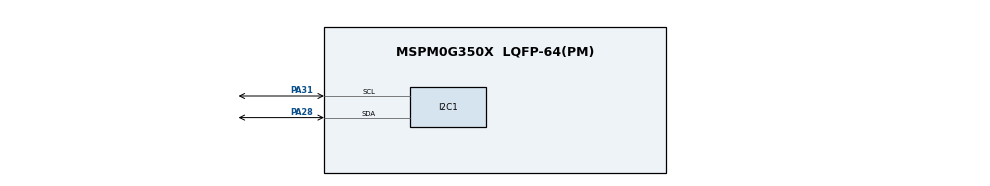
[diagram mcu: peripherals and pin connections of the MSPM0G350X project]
/**
 * @cliArgs --device "MSPM0G350X" --package "LQFP-64(PM)" --part "Default" --product "mspm0_sdk@2.01.00.03"
 * @versions {"tool":"1.20.0+3587"}
 */

/**
 * Import the modules used in this configuration.
 */
const ADC12         = scripting.addModule("/ti/driverlib/ADC12", {}, false);
const ADC121        = ADC12.addInstance();
const ADC122        = ADC12.addInstance();
const CAPTURE       = scripting.addModule("/ti/driverlib/CAPTURE", {}, false);
const CAPTURE1      = CAPTURE.addInstance();
const I2C           = scripting.addModule("/ti/driverlib/I2C", {}, false);
const I2C1          = I2C.addInstance();
const SYSCTL        = scripting.addModule("/ti/driverlib/SYSCTL");
const TIMER         = scripting.addModule("/ti/driverlib/TIMER", {}, false);
const TIMER1        = TIMER.addInstance();
const ProjectConfig = scripting.addModule("/ti/project_config/ProjectConfig");

/**
 * Write custom configuration values to the imported modules.
 */
ADC121.$name                          = "ADC12_0";
ADC121.repeatMode                     = true;
ADC121.adcMem0trig                    = "DL_ADC12_TRIGGER_MODE_TRIGGER_NEXT";
ADC121.configureDMA                   = true;
ADC121.subChanID                      = 1;
ADC121.powerDownMode                  = "DL_ADC12_POWER_DOWN_MODE_MANUAL";
ADC121.trigSrc                        = "DL_ADC12_TRIG_SRC_EVENT";
ADC121.adcMem0chansel                 = "DL_ADC12_INPUT_CHAN_2";
ADC121.sampleTime0                    = "40us";
ADC121.sampCnt                        = 1;
ADC121.enabledDMATriggers             = ["DL_ADC12_DMA_MEM0_RESULT_LOADED"];
ADC121.interruptPriority              = "1";
ADC121.enabledInterrupts              = ["DL_ADC12_INTERRUPT_DMA_DONE"];
ADC121.peripheral.$assign             = "ADC0";
ADC121.DMA_CHANNEL.$name              = "DMA_CH0";
ADC121.DMA_CHANNEL.addressMode        = "f2b";
ADC121.DMA_CHANNEL.srcLength          = "HALF_WORD";
ADC121.DMA_CHANNEL.dstLength          = "HALF_WORD";
ADC121.DMA_CHANNEL.transferMode       = "FULL_CH_REPEAT_SINGLE";
ADC121.DMA_CHANNEL.peripheral.$assign = "DMA_CH0";
ADC121.adcPin2Config.$name            = "ti_driverlib_gpio_GPIOPinGeneric0";

ADC122.$name                    = "ADC12_1";
ADC122.endAdd                   = 1;
ADC122.repeatMode               = true;
ADC122.trigSrc                  = "DL_ADC12_TRIG_SRC_EVENT";
ADC122.adcMem0trig              = "DL_ADC12_TRIGGER_MODE_TRIGGER_NEXT";
ADC122.adcMem1trig              = "DL_ADC12_TRIGGER_MODE_TRIGGER_NEXT";
ADC122.sampleTime0              = "40us";
ADC122.adcMem1chansel           = "DL_ADC12_INPUT_CHAN_1";
ADC122.enabledInterrupts        = ["DL_ADC12_INTERRUPT_DMA_DONE"];
ADC122.configureDMA             = true;
ADC122.subChanID                = 2;
ADC122.enabledDMATriggers       = ["DL_ADC12_DMA_MEM0_RESULT_LOADED"];
ADC122.sampCnt                  = 1;
ADC122.interruptPriority        = "2";
ADC122.peripheral.$assign       = "ADC1";
ADC122.adcPin0Config.$name      = "ti_driverlib_gpio_GPIOPinGeneric2";
ADC122.DMA_CHANNEL.$name        = "DMA_CH1";
ADC122.DMA_CHANNEL.addressMode  = "f2b";
ADC122.DMA_CHANNEL.transferMode = "FULL_CH_REPEAT_SINGLE";
ADC122.DMA_CHANNEL.transferSize = 60;
ADC122.DMA_CHANNEL.srcLength    = "HALF_WORD";
ADC122.DMA_CHANNEL.dstLength    = "HALF_WORD";

const Board = scripting.addModule("/ti/driverlib/Board", {}, false);

CAPTURE1.$name               = "CAPTURE_0";
CAPTURE1.timerClkPrescale    = 256;
CAPTURE1.timerPeriod         = "524.29 ms";
CAPTURE1.timerStartTimer     = true;
CAPTURE1.captMode            = "COMBINED";
CAPTURE1.peripheral.$assign  = "TIMG0";
CAPTURE1.ccp0PinConfig.$name = "ti_driverlib_gpio_GPIOPinGeneric4";

I2C1.$name                             = "I2C_OLED";
I2C1.basicEnableController             = true;
I2C1.basicControllerStandardBusSpeed   = "Fast";
I2C1.intController                     = ["ARBITRATION_LOST","NACK","RXFIFO_TRIGGER","RX_DONE","TX_DONE"];
I2C1.peripheral.sdaPin.$assign         = "PA28";
I2C1.peripheral.sclPin.$assign         = "PA31";
I2C1.sdaPinConfig.hideOutputInversion  = scripting.forceWrite(false);
I2C1.sdaPinConfig.onlyInternalResistor = scripting.forceWrite(false);
I2C1.sdaPinConfig.passedPeripheralType = scripting.forceWrite("Digital");
I2C1.sdaPinConfig.$name                = "ti_driverlib_gpio_GPIOPinGeneric1";
I2C1.sclPinConfig.$name                = "ti_driverlib_gpio_GPIOPinGeneric3";
I2C1.sclPinConfig.hideOutputInversion  = scripting.forceWrite(false);
I2C1.sclPinConfig.onlyInternalResistor = scripting.forceWrite(false);
I2C1.sclPinConfig.passedPeripheralType = scripting.forceWrite("Digital");

SYSCTL.forceDefaultClkConfig = true;

TIMER1.$name                       = "TIMER_0";
TIMER1.timerMode                   = "PERIODIC";
TIMER1.timerStartTimer             = true;
TIMER1.event1ControllerInterruptEn = ["ZERO_EVENT"];
TIMER1.event1PublisherChannel      = 1;
TIMER1.event2ControllerInterruptEn = ["ZERO_EVENT"];
TIMER1.event2PublisherChannel      = 2;
TIMER1.timerPeriod                 = "495us";

ProjectConfig.genLibCMSIS = true;

/**
 * Pinmux solution for unlocked pins/peripherals. This ensures that minor changes to the automatic solver in a future
 * version of the tool will not impact the pinmux you originally saw.  These lines can be completely deleted in order to
 * re-solve from scratch.
 */
ADC121.peripheral.adcPin2.$suggestSolution     = "PA25";
ADC122.peripheral.adcPin0.$suggestSolution     = "PA15";
ADC122.DMA_CHANNEL.peripheral.$suggestSolution = "DMA_CH1";
Board.peripheral.$suggestSolution              = "DEBUGSS";
Board.peripheral.swclkPin.$suggestSolution     = "PA20";
Board.peripheral.swdioPin.$suggestSolution     = "PA19";
CAPTURE1.peripheral.ccp0Pin.$suggestSolution   = "PA12";
I2C1.peripheral.$suggestSolution               = "I2C0";
SYSCTL.peripheral.$suggestSolution             = "SYSCTL";
TIMER1.peripheral.$suggestSolution             = "TIMA0";
